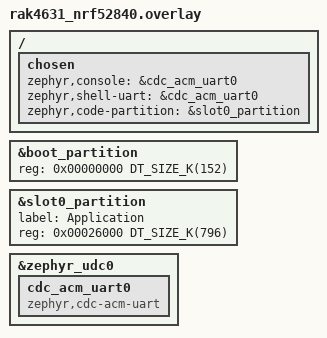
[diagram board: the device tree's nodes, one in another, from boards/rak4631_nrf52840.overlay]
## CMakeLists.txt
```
cmake_minimum_required(VERSION 3.20.0)
find_package(Zephyr REQUIRED HINTS $ENV{ZEPHYR_BASE})
project(sensegate_gateway)

zephyr_include_directories(include)
zephyr_include_directories(../lib)

target_sources(app PRIVATE
    src/main.c
    src/hal_lora.c
    src/role_election.c
    ../lib/aes_ctr.c
    ../lib/payload_packer.c
    ../lib/rolling_buffer.c
    ../lib/store_forward.c
)
```

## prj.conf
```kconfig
CONFIG_SERIAL=y
CONFIG_CONSOLE=y
CONFIG_UART_CONSOLE=y
CONFIG_MAIN_STACK_SIZE=4096
CONFIG_GPIO=y

CONFIG_USB_DEVICE_STACK=y
CONFIG_USB_CDC_ACM=y
CONFIG_UART_INTERRUPT_DRIVEN=y
CONFIG_UART_LINE_CTRL=y
CONFIG_USB_DEVICE_INITIALIZE_AT_BOOT=n

# Adafruit UF2 bootloader flashes app at 0x26000
CONFIG_FLASH_LOAD_OFFSET=0x26000
CONFIG_FLASH_LOAD_SIZE=0x000C7000
CONFIG_ROM_START_OFFSET=0x26000
```

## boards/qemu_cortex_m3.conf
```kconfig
# QEMU has no USB controller — disable USB stack for simulation builds
CONFIG_USB_DEVICE_STACK=n
CONFIG_USB_CDC_ACM=n
CONFIG_UART_INTERRUPT_DRIVEN=n
CONFIG_UART_LINE_CTRL=n

# No UF2 bootloader offset in QEMU
CONFIG_FLASH_LOAD_OFFSET=0x0
CONFIG_FLASH_LOAD_SIZE=0x0
CONFIG_ROM_START_OFFSET=0x0
```

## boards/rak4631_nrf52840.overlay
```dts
/*
 * RAK4631 with Adafruit UF2 bootloader v0.4.3.
 * Application is flashed at 0x26000 (152KB reserved for bootloader).
 * Override the default MCUBoot partition layout from nrf52840_partition.dtsi.
 */

/ {
	chosen {
		zephyr,console        = &cdc_acm_uart0;
		zephyr,shell-uart     = &cdc_acm_uart0;
		zephyr,code-partition = &slot0_partition;
	};
};

&boot_partition {
	reg = <0x00000000 DT_SIZE_K(152)>;
};

&slot0_partition {
	label = "Application";
	reg = <0x00026000 DT_SIZE_K(796)>;
};

&zephyr_udc0 {
	cdc_acm_uart0: cdc_acm_uart0 {
		compatible = "zephyr,cdc-acm-uart";
	};
};
```

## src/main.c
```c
#include <zephyr/kernel.h>
#include <zephyr/sys/printk.h>
#include <zephyr/drivers/uart.h>
#ifdef CONFIG_USB_DEVICE_STACK
#include <zephyr/usb/usb_device.h>
#endif

int main(void)
{
#ifdef CONFIG_USB_DEVICE_STACK
    usb_enable(NULL);

    const struct device *dev = DEVICE_DT_GET(DT_CHOSEN(zephyr_console));
    uint32_t dtr = 0;
    uint32_t tries = 0;
    while (!dtr && tries < 100) {
        uart_line_ctrl_get(dev, UART_LINE_CTRL_DTR, &dtr);
        k_msleep(100);
        tries++;
    }
#endif

    printk("SenseGate alive\n");
    uint32_t i = 0;
    while (1) {
        printk("tick %u\n", i++);
        k_msleep(1000);
    }
}
```

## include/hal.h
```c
#ifndef HAL_H
#define HAL_H

#include <stdint.h>
#include <stddef.h>
#include "rolling_buffer.h"

#define HAL_OK      0
#define HAL_ERROR  -1
#define HAL_FULL   -2
#define HAL_EMPTY  -3

typedef enum {
    HAL_ROLE_SLAVE  = 0,
    HAL_ROLE_MASTER = 1
} hal_role_t;

int        hal_init(void);
int        hal_flash_write(const uint8_t *packet, size_t len);
int        hal_flash_read(uint8_t *packet, size_t len);
int        hal_flash_pending(void);
int        hal_radio_rx(uint8_t *packet, size_t len);  /* riceve da collector */
int        hal_modem_send_sms(const uint8_t *payload, size_t len);
hal_role_t hal_get_role(void);
#endif
```

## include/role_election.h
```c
#ifndef ROLE_ELECTION_H
#define ROLE_ELECTION_H

#include "hal.h"

/*
 * Role election — SenseGate
 *
 * Il ruolo viene eletto UNA SOLA VOLTA al boot
 * leggendo GPIO SIM_DETECT tramite HAL.
 *
 * Adesso: hal_get_role() ritorna un valore simulato
 * Dopo:   hal_get_role() legge il pin fisico SIM_DETECT
 *
 * Il ruolo non cambia durante l'esecuzione.
 * Per cambiarlo: rimuovi/inserisci SIM e riavvia il nodo.
 */

typedef enum {
    ROLE_UNSET  = -1,
    ROLE_SLAVE  =  0,
    ROLE_MASTER =  1
} node_role_t;

/*
 * Chiama questa funzione UNA SOLA VOLTA all'inizio del main.
 * Legge il GPIO, imposta il ruolo, stampa il risultato.
 */
node_role_t role_election_run(void);

/*
 * Ritorna il ruolo corrente (dopo che election_run e' stato chiamato).
 */
node_role_t role_election_get(void);

/*
 * Utility
 */
const char *role_to_string(node_role_t role);

#endif
```

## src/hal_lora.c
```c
/*
 * hal_lora.c — gateway HAL, real hardware implementation
 *
 * Drop-in replacement for hal_sim.c targeting actual Cortex-M hardware.
 * To activate:
 *   1. In CMakeLists.txt replace hal_sim.c with hal_lora.c
 *   2. In prj.conf uncomment CONFIG_LORA=y
 *   3. Add a board overlay with the lora0 DTS alias
 *
 * In QEMU the LoRa device is never ready, so hal_radio_rx() reads a
 * 50-byte hex string from stdin (written by sim_bridge.py) — this is
 * the simulation path that wires the two QEMU nodes together.
 *
 * Stdin packet format (written by sim_bridge.py):
 *   "LORA_RX <HEX>\n"   where HEX is SF_SLOT_SIZE*2 hex chars (100 chars)
 */

#include "hal.h"
#include "store_forward.h"
#include "rolling_buffer.h"
#include "lora_link.h"
#include <zephyr/kernel.h>
#include <zephyr/device.h>
#include <zephyr/drivers/lora.h>
#include <zephyr/sys/printk.h>
#include <string.h>

#ifdef CONFIG_LORA
static const struct device *lora_dev = DEVICE_DT_GET(LORA_NODE);
#else
static const struct device *lora_dev;
#endif

static bool lora_ready;
static hal_role_t sim_role = HAL_ROLE_MASTER;

/* ── helpers ────────────────────────────────────────────────────────────── */

static uint8_t hex_nibble(char c)
{
    if (c >= '0' && c <= '9') return c - '0';
    if (c >= 'a' && c <= 'f') return c - 'a' + 10;
    if (c >= 'A' && c <= 'F') return c - 'A' + 10;
    return 0;
}

static int hex_to_bytes(const char *hex, uint8_t *out, size_t out_len)
{
    for (size_t i = 0; i < out_len; i++) {
        out[i] = (hex_nibble(hex[i * 2]) << 4) | hex_nibble(hex[i * 2 + 1]);
    }
    return 0;
}

/* ── init ───────────────────────────────────────────────────────────────── */

int hal_init(void)
{
    printk("[HAL GW HW] Initializing gateway\n");

    sf_init();
    rolling_buffer_init();

#ifdef CONFIG_LORA
    lora_ready = device_is_ready(lora_dev);
#else
    lora_ready = false;
#endif

    if (lora_ready) {
        struct lora_modem_config cfg = {
            .frequency    = LORA_FREQUENCY,
            .bandwidth    = LORA_BANDWIDTH,
            .datarate     = LORA_DATARATE,
            .coding_rate  = LORA_CODING_RATE,
            .preamble_len = LORA_PREAMBLE_LEN,
            .tx_power     = LORA_TX_POWER,
            .tx           = false,   /* gateway is RX */
        };
        if (lora_config(lora_dev, &cfg) != 0) {
            printk("[HAL GW HW] ERROR: lora_config failed\n");
            lora_ready = false;
        } else {
            printk("[HAL GW HW] LoRa configured @ %d Hz SF%d (RX mode)\n",
                   LORA_FREQUENCY, 10);
        }
    } else {
        printk("[HAL GW HW] LoRa device not ready — stdin sim path active\n");
    }

    printk("[HAL GW HW] Ready. Role: %s\n",
           sim_role == HAL_ROLE_MASTER ? "MASTER" : "SLAVE");
    return SG_HAL_OK;
}

/* ── flash (store-and-forward) ──────────────────────────────────────────── */

int hal_flash_write(const uint8_t *packet, size_t len)
{
    if (len != SF_SLOT_SIZE) return SG_HAL_ERROR;
    return (sf_write(packet) == SF_OK) ? SG_HAL_OK : SG_HAL_FULL;
}

int hal_flash_read(uint8_t *packet, size_t len)
{
    if (len != SF_SLOT_SIZE) return SG_HAL_ERROR;
    return (sf_read(packet) == SF_OK) ? SG_HAL_OK : SG_HAL_EMPTY;
}

int hal_flash_pending(void)
{
    return sf_pending();
}

/* ── radio RX ───────────────────────────────────────────────────────────── */

int hal_radio_rx(uint8_t *packet, size_t len)
{
    if (len < SF_SLOT_SIZE) return SG_HAL_ERROR;

    if (lora_ready) {
        int16_t rssi;
        int8_t  snr;
        int ret = lora_recv(lora_dev, packet, len,
                            K_MSEC(LORA_RX_TIMEOUT_MS), &rssi, &snr);
        if (ret < 0) {
            printk("[HAL GW HW] lora_recv timeout or error (%d)\n", ret);
            return SG_HAL_ERROR;
        }
        printk("[HAL GW HW] LoRa RX %d bytes  RSSI=%d dBm  SNR=%d dB\n",
               ret, rssi, snr);
        return SG_HAL_OK;
    }

    /*
     * QEMU simulation path.
     * sim_bridge.py writes "LORA_RX <100-char-hex>\n" to gateway stdin
     * after it captures each LoRa TX line from the collector QEMU process.
     */
    char line[128];
    if (fgets(line, sizeof(line), stdin) == NULL) {
        return SG_HAL_ERROR;
    }

    /* Expect "LORA_RX AABB...CC\n" */
    if (strncmp(line, "LORA_RX ", 8) != 0) {
        printk("[HAL GW SIM] Unexpected stdin line: %s", line);
        return SG_HAL_ERROR;
    }

    const char *hex = line + 8;
    size_t hex_len = strlen(hex);
    /* Strip trailing newline */
    while (hex_len > 0 && (hex[hex_len-1] == '\n' || hex[hex_len-1] == '\r')) {
        hex_len--;
    }

    if (hex_len != SF_SLOT_SIZE * 2) {
        printk("[HAL GW SIM] Bad hex length %d (expected %d)\n",
               (int)hex_len, (int)(SF_SLOT_SIZE * 2));
        return SG_HAL_ERROR;
    }

    hex_to_bytes(hex, packet, SF_SLOT_SIZE);
    printk("[HAL GW SIM] LoRa RX simulated via stdin (%d bytes)\n", (int)SF_SLOT_SIZE);
    return SG_HAL_OK;
}

/* ── NB-IoT modem ───────────────────────────────────────────────────────── */

int hal_modem_send_sms(const uint8_t *payload, size_t len)
{
    printk("[GATEWAY] NB-IoT TX simulation: ");
    for (size_t i = 0; i < len; i++) {
        printk("%02X", payload[i]);
    }
    printk("\n");
    return SG_HAL_OK;
}

/* ── role ───────────────────────────────────────────────────────────────── */

hal_role_t hal_get_role(void)
{
    return sim_role;
}

void hal_sim_set_role(hal_role_t role)
{
    sim_role = role;
}
```

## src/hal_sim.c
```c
#include "hal.h"
#include "store_forward.h"
#include "rolling_buffer.h"
#include <string.h>
#include <zephyr/sys/printk.h>

static hal_role_t sim_role = HAL_ROLE_MASTER; // static has_role_t sim_role = HAL_ROLE_SLAVE;
static uint16_t   sim_seq  = 0;

/* Pacchetto finto — simula quello che manda il collector */
static const uint8_t SIM_PACKET[SF_SLOT_SIZE] = {
    0x5B,0xDE,0xB6,0x99,0x9B,0x33,0x97,0x1B,
    0x85,0xA4,0x59,0x2D,0xE3,0x35,0xCA,0x3E,
    0x44,0x75,0x8B,
    0x00,0x00,0x00,0x00,0x00,0x00,0x00,0x00,
    0x00,0x00,0x00,0x00,0x00,0x00,0x00,0x00,
    0x00,0x00,0x00
};

int hal_init(void)
{
    printk("[HAL GW SIM] Initializing gateway\n");
    sf_init();
    rolling_buffer_init();
    printk("[HAL GW SIM] Ready. Role: %s\n",
           sim_role == HAL_ROLE_MASTER ? "MASTER" : "SLAVE");
    return HAL_OK;
}

int hal_flash_write(const uint8_t *packet, size_t len)
{
    if (len != SF_SLOT_SIZE) return HAL_ERROR;
    return (sf_write(packet) == SF_OK) ? HAL_OK : HAL_FULL;
}

int hal_flash_read(uint8_t *packet, size_t len)
{
    if (len != SF_SLOT_SIZE) return HAL_ERROR;
    return (sf_read(packet) == SF_OK) ? HAL_OK : HAL_EMPTY;
}

int hal_flash_pending(void)
{
    return sf_pending();
}

int hal_radio_rx(uint8_t *packet, size_t len)
{
    /*
     * Simula ricezione LoRa dal collector.
     * Adesso: copia un pacchetto finto
     * Dopo:   driver Zephyr LoRa RX:
     *         lora_recv(&lora_dev, packet, len, K_FOREVER, &rssi, &snr)
     */
    if (len < SF_SLOT_SIZE) return HAL_ERROR;
    memcpy(packet, SIM_PACKET, SF_SLOT_SIZE);
    /* Varia leggermente per simulare pacchetti diversi */
    packet[0] ^= (uint8_t)sim_seq;
    sim_seq++;
    printk("[HAL GW SIM] LoRa RX simulated (seq %u)\n", sim_seq);
    return HAL_OK;
}

int hal_modem_send_sms(const uint8_t *payload, size_t len)
{
    /*
     * Simula invio SMS NB-IoT.
     * Dopo: AT+CMGF=0 + AT+CMGS + payload hex + CTRL+Z
     */
    printk("[HAL GW SIM] NB-IoT SMS (%d bytes): ", len);
    for (size_t i = 0; i < len; i++) {
        printk("%02X", payload[i]);
    }
    printk("\n");
    return HAL_OK;
}

hal_role_t hal_get_role(void)
{
    
    return sim_role;
}

void hal_sim_set_role(hal_role_t role)
{
    sim_role = role;
}
```

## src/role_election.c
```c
#include "role_election.h"
#include <zephyr/sys/printk.h>

static node_role_t current_role = ROLE_UNSET;

node_role_t role_election_run(void)
{
    printk("[ROLE] Reading SIM_DETECT GPIO...\n");

    /*
     * Legge il ruolo tramite HAL.
     * Adesso: valore simulato impostato con hal_sim_set_role()
     * Dopo:   gpio_pin_get(sim_detect_dev, SIM_DETECT_PIN)
     */
    hal_role_t hal_role = hal_get_role();

    if (hal_role == HAL_ROLE_MASTER) {
        current_role = ROLE_MASTER;
    } else {
        current_role = ROLE_SLAVE;
    }

    printk("[ROLE] Elected: %s\n", role_to_string(current_role));

    if (current_role == ROLE_MASTER) {
        printk("[ROLE] SIM present -> NB-IoT modem will be active\n");
        printk("[ROLE] Responsible for SMS uplink to cloud\n");
    } else {
        printk("[ROLE] No SIM -> LoRa only\n");
        printk("[ROLE] Packets forwarded to master via LoRa\n");
    }

    return current_role;
}

node_role_t role_election_get(void)
{
    return current_role;
}

const char *role_to_string(node_role_t role)
{
    switch (role) {
        case ROLE_MASTER: return "MASTER";
        case ROLE_SLAVE:  return "SLAVE";
        default:          return "UNSET";
    }
}
```
